# MSP430F5529 register map
Vendor: msp430gen; File version: v0.4.0-10-gd4db4bc
Registers are 8-bit, read-write, reset 0x0 unless marked. A register's access mark holds for its fields unless they carry their own. Offsets are from the block's base; [hi:lo] are bit positions; lines under a group give offsets from that group; {n}, {i} and the like mark numbered series.

## TIMER1_A3 — Timer A3
Base 0x00000380
Same registers: TIMER2_A3 0x00000400
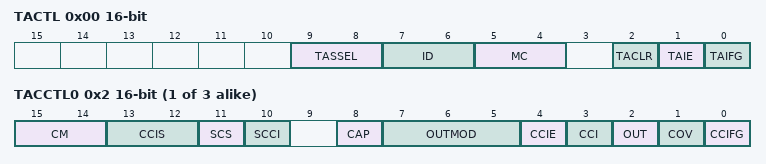
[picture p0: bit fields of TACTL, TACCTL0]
0x00 TACTL 16-bit — Timer1_A3 Control
  [9:8] TASSEL — Timer A clock source select 1
    0=Timer A clock source select: 0 - TACLK; 1=Timer A clock source select: 1 - ACLK; 2=Timer A clock source select: 2 - SMCLK; 3=Timer A clock source select: 3 - INCLK
  [7:6] ID — Timer A clock input divider 1
    0=Timer A input divider: 0 - /1; 1=Timer A input divider: 1 - /2; 2=Timer A input divider: 2 - /4; 3=Timer A input divider: 3 - /8
  [5:4] MC — Timer A mode control 1
    0=Timer A mode control: 0 - Stop; 1=Timer A mode control: 1 - Up to CCR0; 2=Timer A mode control: 2 - Continuous up; 3=Timer A mode control: 3 - Up/Down
  [2] TACLR — Timer A counter clear
  [1] TAIE — Timer A counter interrupt enable
  [0] TAIFG — Timer A counter interrupt flag
{0x2+2i} TACCTL{i} 16-bit (i=0..2) — Timer1_A3 Capture/Compare Control {i}
  [15:14] CM — Capture mode 1
    0=Capture mode: 0 - disabled; 1=Capture mode: 1 - pos. edge; 2=Capture mode: 1 - neg. edge; 3=Capture mode: 1 - both edges
  [13:12] CCIS — Capture input select 1
    0=Capture input select: 0 - CCIxA; 1=Capture input select: 1 - CCIxB; 2=Capture input select: 2 - GND; 3=Capture input select: 3 - Vcc
  [11] SCS — Capture sychronize
  [10] SCCI — Latched capture signal (read)
  [8] CAP — Capture mode: 1 /Compare mode : 0
  [7:5] OUTMOD — Output mode 2
    0=PWM output mode: 0 - output only; 1=PWM output mode: 1 - set; 2=PWM output mode: 2 - PWM toggle/reset; 3=PWM output mode: 3 - PWM set/reset; 4=PWM output mode: 4 - toggle; 5=PWM output mode: 5 - Reset; 6=PWM output mode: 6 - PWM toggle/set; 7=PWM output mode: 7 - PWM reset/set
  [4] CCIE — Capture/compare interrupt enable
  [3] CCI — Capture input signal (read)
  [2] OUT — PWM Output signal if output mode 0
  [1] COV — Capture/compare overflow flag
  [0] CCIFG — Capture/compare interrupt flag
0x10 TAR 16-bit — Timer1_A3
  [15:0] TAR — Timer A Counter Register
{0x12+2i} TACCR{i} 16-bit (i=0..2) — Timer1_A3 Capture/Compare {i}
  [15:0] TACCR{i} — Timer A Capture/Compare register {i}
0x20 TA1EX0 16-bit — Timer1_A3 Expansion Register 0
  [2:0] TAIDEX — Timer A Input divider expansion Bit: 0
    {v}=Timer A Input divider expansion : /{v+1} (v=0..7)
0x2E TAIV 16-bit — Timer1_A3 Interrupt Vector Word
  [3:0] TAIV — Timer A Interrupt Vector value
    0=NONE (No interrupt pending); 2=TACCR1 (Capture/Compare 1); 4=TACCR2 (Capture/Compare 2); 10=TAIFG (Timer overflow)

## TIMER_0_B7
Base 0x000003C0
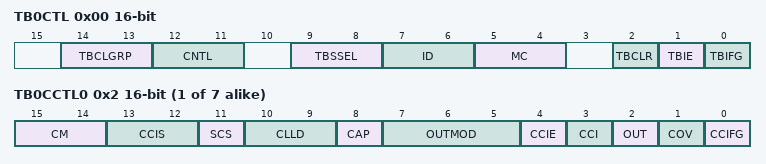
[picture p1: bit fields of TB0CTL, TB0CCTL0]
0x00 TB0CTL 16-bit — Timer0_B7 Control
  [14:13] TBCLGRP — Timer0_B7 Compare latch load group 1
    0=Timer0_B7 Group: 0 - individually; 1=Timer0_B7 Group: 1 - 3 groups (1-2; 2=Timer0_B7 Group: 2 - 2 groups (1-3; 3=Timer0_B7 Group: 3 - 1 group (all)
  [12:11] CNTL — Counter lenght 1
    0=Counter lenght: 16 bit; 1=Counter lenght: 12 bit; 2=Counter lenght: 10 bit; 3=Counter lenght: 8 bit
  [9:8] TBSSEL — Clock source 1
    0=Clock Source: TBCLK; 1=Clock Source: ACLK; 2=Clock Source: SMCLK; 3=Clock Source: INCLK
  [7:6] ID — Timer0_B7 clock input divider 1
    0=Timer A input divider: 0 - /1; 1=Timer A input divider: 1 - /2; 2=Timer A input divider: 2 - /4; 3=Timer A input divider: 3 - /8
  [5:4] MC — Timer0_B7 mode control 1
    0=Timer A mode control: 0 - Stop; 1=Timer A mode control: 1 - Up to CCR0; 2=Timer A mode control: 2 - Continuous up; 3=Timer A mode control: 3 - Up/Down
  [2] TBCLR — Timer0_B7 counter clear
  [1] TBIE — Timer0_B7 interrupt enable
  [0] TBIFG — Timer0_B7 interrupt flag
{0x2+2i} TB0CCTL{i} 16-bit (i=0..6) — Timer0_B7 Capture/Compare Control {i}
  [15:14] CM — Capture mode 1
    0=Capture mode: 0 - disabled; 1=Capture mode: 1 - pos. edge; 2=Capture mode: 1 - neg. edge; 3=Capture mode: 1 - both edges
  [13:12] CCIS — Capture input select 1
    0=Capture input select: 0 - CCIxA; 1=Capture input select: 1 - CCIxB; 2=Capture input select: 2 - GND; 3=Capture input select: 3 - Vcc
  [11] SCS — Capture sychronize
  [10:9] CLLD — Compare latch load source 1
    0=Compare latch load sourec : 0 - immediate; 1=Compare latch load sourec : 1 - TBR counts to 0; 2=Compare latch load sourec : 2 - up/down; 3=Compare latch load sourec : 3 - TBR counts to TBCTL0
  [8] CAP — Capture mode: 1 /Compare mode : 0
  [7:5] OUTMOD — Output mode 2
    0=PWM output mode: 0 - output only; 1=PWM output mode: 1 - set; 2=PWM output mode: 2 - PWM toggle/reset; 3=PWM output mode: 3 - PWM set/reset; 4=PWM output mode: 4 - toggle; 5=PWM output mode: 5 - Reset; 6=PWM output mode: 6 - PWM toggle/set; 7=PWM output mode: 7 - PWM reset/set
  [4] CCIE — Capture/compare interrupt enable
  [3] CCI — Capture input signal (read)
  [2] OUT — PWM Output signal if output mode 0
  [1] COV — Capture/compare overflow flag
  [0] CCIFG — Capture/compare interrupt flag
0x10 TB0R 16-bit — Timer0_B7
{0x12+2i} TB0CCR{i} 16-bit (i=0..6) — Timer0_B7 Capture/Compare {i}
0x20 TB0EX0 16-bit — Timer0_B7 Expansion Register 0
  [2:0] TBIDEX — Timer0_B7 Input divider expansion Bit: 0
    {v}=Timer0_B7 Input divider expansion : /{v+1} (v=0..7)
0x2E TB0IV 16-bit — Timer0_B7 Interrupt Vector Word

## MPY_16 — MPY 16 Multiplier 16 Bit Mode
Base 0x000004C0
0x00 MPY 16-bit — Multiply Unsigned/Operand 1
0x02 MPYS 16-bit — Multiply Signed/Operand 1
0x04 MAC 16-bit — Multiply Unsigned and Accumulate/Operand 1
0x06 MACS 16-bit — Multiply Signed and Accumulate/Operand 1
0x08 OP2 16-bit — Operand 2
0x0A RESLO 16-bit — Result Low Word
0x0C RESHI 16-bit — Result High Word
0x0E SUMEXT 16-bit — Sum Extend
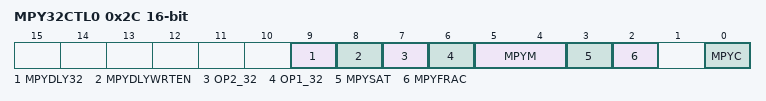
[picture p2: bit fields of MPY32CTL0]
0x2C MPY32CTL0 16-bit — MPY32 Control Register 0
  [9] MPYDLY32 — Delayed write mode
  [8] MPYDLYWRTEN — Delayed write enable
  [7] OP2_32 — Bit-width of operand 2 0:16Bit / 1:32Bit
  [6] OP1_32 — Bit-width of operand 1 0:16Bit / 1:32Bit
  [5:4] MPYM — Multiplier mode Bit:0
    0=Multiplier mode: MPY; 1=Multiplier mode: MPYS; 2=Multiplier mode: MAC; 3=Multiplier mode: MACS
  [3] MPYSAT — Saturation mode
  [2] MPYFRAC — Fractional mode
  [0] MPYC — Carry of the multiplier

## MPY_32 — MPY 32 Multiplier 32 Bit Mode
Base 0x000004D0
0x00 MPY32L 16-bit — 32-bit operand 1 - multiply - low word
0x02 MPY32H 16-bit — 32-bit operand 1 - multiply - high word
0x04 MPYS32L 16-bit — 32-bit operand 1 - signed multiply - low word
0x06 MPYS32H 16-bit — 32-bit operand 1 - signed multiply - high word
0x08 MAC32L 16-bit — 32-bit operand 1 - multiply accumulate - low word
0x0A MAC32H 16-bit — 32-bit operand 1 - multiply accumulate - high word
0x0C MACS32L 16-bit — 32-bit operand 1 - signed multiply accumulate - low word
0x0E MACS32H 16-bit — 32-bit operand 1 - signed multiply accumulate - high word
0x10 OP2L 16-bit — 32-bit operand 2 - low word
0x12 OP2H 16-bit — 32-bit operand 2 - high word
0x14 RES0 16-bit — 32x32-bit result 0 - least significant word
0x16 RES1 16-bit — 32x32-bit result 1
0x18 RES2 16-bit — 32x32-bit result 2
0x1A RES3 16-bit — 32x32-bit result 3 - most significant word
